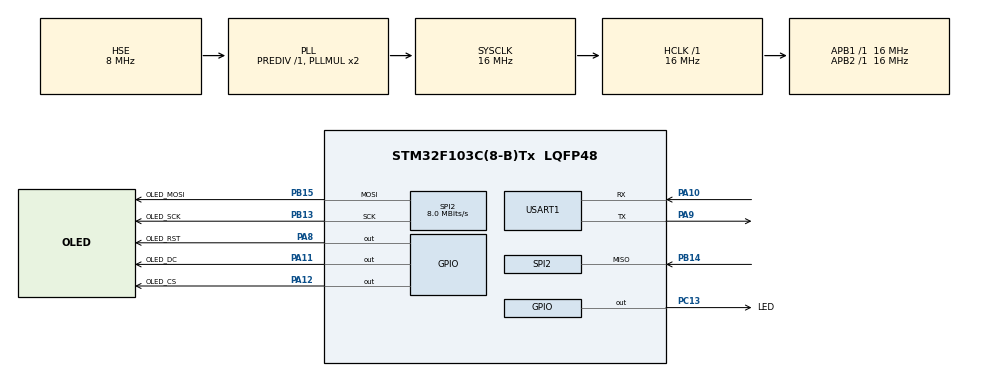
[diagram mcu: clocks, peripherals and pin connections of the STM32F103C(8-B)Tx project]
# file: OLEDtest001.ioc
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Mcu.Family=STM32F1
Mcu.Name=STM32F103C(8-B)Tx
Mcu.Package=LQFP48
NVIC.PriorityGroup=NVIC_PRIORITYGROUP_4
NVIC.USART1_IRQn=true\:0\:0\:false\:false\:true\:true\:true
PA10.Mode=Asynchronous
PA10.Signal=USART1_RX
PA11.GPIO_Label=OLED_DC
PA11.Signal=GPIO_Output
PA12.GPIO_Label=OLED_CS
PA12.Signal=GPIO_Output
PA13.Mode=JTAG_4_pins
PA13.Signal=SYS_JTMS-SWDIO
PA14.Mode=JTAG_4_pins
PA14.Signal=SYS_JTCK-SWCLK
PA15.Mode=JTAG_4_pins
PA15.Signal=SYS_JTDI
PA8.GPIO_Label=OLED_RST
PA8.Signal=GPIO_Output
PA9.Mode=Asynchronous
PA9.Signal=USART1_TX
PB13.GPIO_Label=OLED_SCK
PB13.Mode=Full_Duplex_Master
PB13.Signal=SPI2_SCK
PB14.Mode=Full_Duplex_Master
PB14.Signal=SPI2_MISO
PB15.GPIO_Label=OLED_MOSI
PB15.Mode=Full_Duplex_Master
PB15.Signal=SPI2_MOSI
PB3.Mode=JTAG_4_pins
PB3.Signal=SYS_JTDO-TRACESWO
PC13-TAMPER-RTC.GPIO_Label=LED
PC13-TAMPER-RTC.PinState=GPIO_PIN_SET
PC13-TAMPER-RTC.Signal=GPIO_Output
PD0-OSC_IN.Mode=HSE-External-Oscillator
PD0-OSC_IN.Signal=RCC_OSC_IN
PD1-OSC_OUT.Mode=HSE-External-Oscillator
PD1-OSC_OUT.Signal=RCC_OSC_OUT
ProjectManager.HeapSize=0x200
ProjectManager.StackSize=0x400
ProjectManager.TargetToolchain=MDK-ARM V5.27
RCC.AHBFreq_Value=16000000
RCC.APB1Freq_Value=16000000
RCC.APB1TimFreq_Value=16000000
RCC.APB2Freq_Value=16000000
RCC.APB2TimFreq_Value=16000000
RCC.HCLKFreq_Value=16000000
RCC.PLLSourceVirtual=RCC_PLLSOURCE_HSE
RCC.SYSCLKFreq_VALUE=16000000
RCC.SYSCLKSource=RCC_SYSCLKSOURCE_PLLCLK
RCC.USBFreq_Value=16000000
SPI2.CalculateBaudRate=8.0 MBits/s
SPI2.Direction=SPI_DIRECTION_2LINES
SPI2.Mode=SPI_MODE_MASTER
SPI2.VirtualType=VM_MASTER
USART1.VirtualMode=VM_ASYNC
VP_TIM1_VS_ClockSourceINT.Mode=Internal
VP_TIM1_VS_ClockSourceITR.Mode=TriggerSource_ITR0
board=custom

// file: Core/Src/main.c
/* USER CODE BEGIN Header */
/**
  ******************************************************************************
  * @file           : main.c
  * @brief          : Main program body
  ******************************************************************************
  * @attention
  *
  * <h2><center>&copy; Copyright (c) 2021 STMicroelectronics.
  * All rights reserved.</center></h2>
  *
  * This software component is licensed by ST under BSD 3-Clause license,
  * the "License"; You may not use this file except in compliance with the
  * License. You may obtain a copy of the License at:
  *                        opensource.org/licenses/BSD-3-Clause
  *
  ******************************************************************************
  */
/* USER CODE END Header */
#include "main.h"
#include "spi.h"
#include "tim.h"
#include "usart.h"
#include "gpio.h"
#include "oled.h"
//#include "bmp.h"

/* USER CODE BEGIN Includes */
#define u8 uint8_t
extern uint8_t Rec_rxbuf[100];
extern uint8_t rx_temp;
/* USER CODE END Includes */

/* USER CODE BEGIN PTD */

void HAL_UART_RxCpltCallback(UART_HandleTypeDef *huart)
{
	if(huart->Instance == USART1)
	{
		Rec_Interrupt();
	}
}

/* USER CODE END PTD */

void SystemClock_Config(void);

int main(void)
{

  /* MCU Configuration--------------------------------------------------------*/

  /* Reset of all peripherals, Initializes the Flash interface and the Systick. */
  HAL_Init();

  /* Configure the system clock */
  SystemClock_Config();

  /* Initialize all configured peripherals */
  MX_GPIO_Init();
  MX_USART1_UART_Init();
  MX_TIM1_Init();
  MX_SPI2_Init();
  /* USER CODE BEGIN 2 */
	OLED_Init();
	OLED_ColorTurn(0);//0正常显示，1 反色显示
	OLED_DisplayTurn(0);//0正常显示 1 屏幕翻转显示
	OLED_Refresh(); //每次更改后，需要刷新
  HAL_UART_Receive_IT(&huart1,&rx_temp, 1);

  /* USER CODE END 2 */

  /* Infinite loop */
  /* USER CODE BEGIN WHILE */
  while (1)
  {
		//printf("串口输出测试\r\n");
		HAL_Delay(1000);
		printf("%s\r\n",Rec_rxbuf);

    /* USER CODE END WHILE */

  }
}

void SystemClock_Config(void)
{
  RCC_OscInitTypeDef RCC_OscInitStruct = {0};
  RCC_ClkInitTypeDef RCC_ClkInitStruct = {0};

  /** Initializes the RCC Oscillators according to the specified parameters
  * in the RCC_OscInitTypeDef structure.
  */
  RCC_OscInitStruct.OscillatorType = RCC_OSCILLATORTYPE_HSE;
  RCC_OscInitStruct.HSEState = RCC_HSE_ON;
  RCC_OscInitStruct.HSEPredivValue = RCC_HSE_PREDIV_DIV1;
  RCC_OscInitStruct.HSIState = RCC_HSI_ON;
  RCC_OscInitStruct.PLL.PLLState = RCC_PLL_ON;
  RCC_OscInitStruct.PLL.PLLSource = RCC_PLLSOURCE_HSE;
  RCC_OscInitStruct.PLL.PLLMUL = RCC_PLL_MUL2;
  if (HAL_RCC_OscConfig(&RCC_OscInitStruct) != HAL_OK)
  {
    Error_Handler();
  }
  /** Initializes the CPU, AHB and APB buses clocks
  */
  RCC_ClkInitStruct.ClockType = RCC_CLOCKTYPE_HCLK|RCC_CLOCKTYPE_SYSCLK
                              |RCC_CLOCKTYPE_PCLK1|RCC_CLOCKTYPE_PCLK2;
  RCC_ClkInitStruct.SYSCLKSource = RCC_SYSCLKSOURCE_PLLCLK;
  RCC_ClkInitStruct.AHBCLKDivider = RCC_SYSCLK_DIV1;
  RCC_ClkInitStruct.APB1CLKDivider = RCC_HCLK_DIV1;
  RCC_ClkInitStruct.APB2CLKDivider = RCC_HCLK_DIV1;

  if (HAL_RCC_ClockConfig(&RCC_ClkInitStruct, FLASH_LATENCY_0) != HAL_OK)
  {
    Error_Handler();
  }
}

void Error_Handler(void)
{
  __disable_irq();
  while (1)
  {
  }
}

/************************ (C) COPYRIGHT STMicroelectronics *****END OF FILE****/
